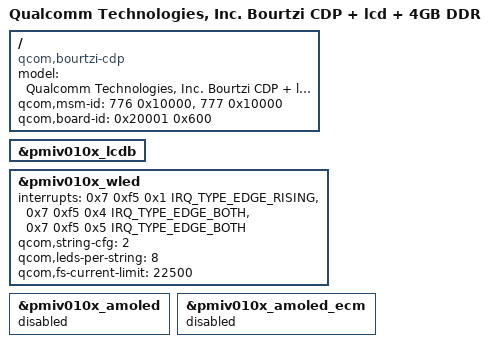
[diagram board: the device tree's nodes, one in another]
// SPDX-License-Identifier: BSD-3-Clause
/*
 * Copyright (c) Qualcomm Technologies, Inc. and/or its subsidiaries.
 */

/dts-v1/;
/plugin/;

#include "bourtzi-cdp-4gb.dtsi"

/ {
	model = "Qualcomm Technologies, Inc. Bourtzi CDP + lcd + 4GB DDR";
	compatible = "qcom,bourtzi-cdp", "qcom,bourtzip-cdp", "qcom,bourtzi", "qcom,bourtzip", "qcom,cdp";
	qcom,msm-id = <776 0x10000>, <777 0x10000>;
	qcom,board-id = <0x20001 0x600>;
};

&pmiv010x_lcdb {
	status = "okay";
};

&pmiv010x_wled {
	interrupts = <0x7 0xf5 0x1 IRQ_TYPE_EDGE_RISING>,
		     <0x7 0xf5 0x4 IRQ_TYPE_EDGE_BOTH>,
		     <0x7 0xf5 0x5 IRQ_TYPE_EDGE_BOTH>;
	interrupt-names = "ovp-irq", "pre-flash-irq", "flash-irq";
	qcom,string-cfg = <2>;
	qcom,leds-per-string = <8>;
	qcom,fs-current-limit = <22500>;
	status = "okay";
};

&pmiv010x_amoled {
	status = "disabled";
};

&pmiv010x_amoled_ecm {
	status = "disabled";
};
